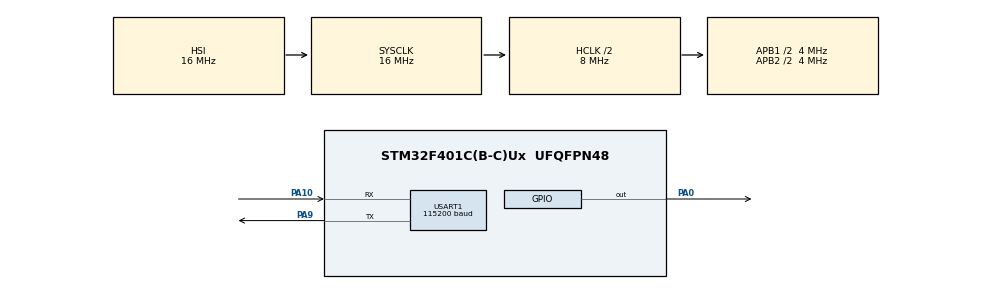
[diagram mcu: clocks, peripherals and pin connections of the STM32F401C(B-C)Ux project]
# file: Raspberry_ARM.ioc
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Mcu.Family=STM32F4
Mcu.Name=STM32F401C(B-C)Ux
Mcu.Package=UFQFPN48
NVIC.PriorityGroup=NVIC_PRIORITYGROUP_4
NVIC.USART1_IRQn=true\:0\:0\:false\:false\:true\:true\:true\:true
PA0-WKUP.Signal=GPIO_Output
PA10.Mode=Asynchronous
PA10.Signal=USART1_RX
PA9.Mode=Asynchronous
PA9.Signal=USART1_TX
ProjectManager.HeapSize=0x200
ProjectManager.StackSize=0x400
ProjectManager.TargetToolchain=STM32CubeIDE
RCC.AHBCLKDivider=RCC_SYSCLK_DIV2
RCC.AHBFreq_Value=8000000
RCC.APB1CLKDivider=RCC_HCLK_DIV2
RCC.APB1Freq_Value=4000000
RCC.APB1TimFreq_Value=8000000
RCC.APB2CLKDivider=RCC_HCLK_DIV2
RCC.APB2Freq_Value=4000000
RCC.APB2TimFreq_Value=8000000
RCC.CortexFreq_Value=8000000
RCC.HCLKFreq_Value=8000000
RCC.HSE_VALUE=25000000
RCC.HSI_VALUE=16000000
RCC.LSE_VALUE=32768
RCC.SYSCLKFreq_VALUE=16000000
RCC.VCOOutputFreq_Value=192000000
USART1.BaudRate=115200
USART1.VirtualMode=VM_ASYNC
board=custom

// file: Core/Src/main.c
/* USER CODE BEGIN Header */
/**
 ******************************************************************************
 * @file           : main.c
 * @brief          : Main program body
 ******************************************************************************
 * @attention
 *
 * Copyright (c) 2023 STMicroelectronics.
 * All rights reserved.
 *
 * This software is licensed under terms that can be found in the LICENSE file
 * in the root directory of this software component.
 * If no LICENSE file comes with this software, it is provided AS-IS.
 *
 ******************************************************************************
 */
/* USER CODE END Header */
#include "main.h"

/* USER CODE BEGIN PD */
#define SIZE_OF_BUFFER    1
#define LED_PORT          GPIOA
#define LED_PIN           GPIO_PIN_0
/* USER CODE END PD */

UART_HandleTypeDef huart1;

void SystemClock_Config(void);
static void MX_GPIO_Init(void);
static void MX_USART1_UART_Init(void);
/* USER CODE BEGIN PFP */
void LED_ON(void);
void LED_OFF(void);
/* USER CODE END PFP */

int main(void)
{
  /* USER CODE BEGIN 1 */
	uint8_t RecieveBuffer = 22;
  /* USER CODE END 1 */

  /* MCU Configuration--------------------------------------------------------*/

  /* Reset of all peripherals, Initializes the Flash interface and the Systick. */
  HAL_Init();

  /* Configure the system clock */
  SystemClock_Config();

  /* Initialize all configured peripherals */
  MX_GPIO_Init();
  MX_USART1_UART_Init();
  /* USER CODE BEGIN 2 */
//	HAL_GPIO_WritePin(GPIOA, GPIO_PIN_0, GPIO_PIN_SET);

  /* USER CODE END 2 */

  /* Infinite loop */
	while (1)
	{

    /* USER CODE BEGIN 3 */
		HAL_UART_Receive(&huart1, &RecieveBuffer,SIZE_OF_BUFFER, 20);
		if(RecieveBuffer == 'O'){
			LED_ON();
		}
		else if (RecieveBuffer == 'F'){
			LED_OFF();
		}
		else{
			//Do Nothing
		}
	}
  /* USER CODE END 3 */
}

void SystemClock_Config(void)
{
  RCC_OscInitTypeDef RCC_OscInitStruct = {0};
  RCC_ClkInitTypeDef RCC_ClkInitStruct = {0};

  /** Configure the main internal regulator output voltage
  */
  __HAL_RCC_PWR_CLK_ENABLE();
  __HAL_PWR_VOLTAGESCALING_CONFIG(PWR_REGULATOR_VOLTAGE_SCALE2);

  /** Initializes the RCC Oscillators according to the specified parameters
  * in the RCC_OscInitTypeDef structure.
  */
  RCC_OscInitStruct.OscillatorType = RCC_OSCILLATORTYPE_HSI;
  RCC_OscInitStruct.HSIState = RCC_HSI_ON;
  RCC_OscInitStruct.HSICalibrationValue = RCC_HSICALIBRATION_DEFAULT;
  RCC_OscInitStruct.PLL.PLLState = RCC_PLL_NONE;
  if (HAL_RCC_OscConfig(&RCC_OscInitStruct) != HAL_OK)
  {
    Error_Handler();
  }

  /** Initializes the CPU, AHB and APB buses clocks
  */
  RCC_ClkInitStruct.ClockType = RCC_CLOCKTYPE_HCLK|RCC_CLOCKTYPE_SYSCLK
                              |RCC_CLOCKTYPE_PCLK1|RCC_CLOCKTYPE_PCLK2;
  RCC_ClkInitStruct.SYSCLKSource = RCC_SYSCLKSOURCE_HSI;
  RCC_ClkInitStruct.AHBCLKDivider = RCC_SYSCLK_DIV2;
  RCC_ClkInitStruct.APB1CLKDivider = RCC_HCLK_DIV2;
  RCC_ClkInitStruct.APB2CLKDivider = RCC_HCLK_DIV2;

  if (HAL_RCC_ClockConfig(&RCC_ClkInitStruct, FLASH_LATENCY_0) != HAL_OK)
  {
    Error_Handler();
  }
}

static void MX_USART1_UART_Init(void)
{

  huart1.Instance = USART1;
  huart1.Init.BaudRate = 9600;
  huart1.Init.WordLength = UART_WORDLENGTH_8B;
  huart1.Init.StopBits = UART_STOPBITS_1;
  huart1.Init.Parity = UART_PARITY_NONE;
  huart1.Init.Mode = UART_MODE_TX_RX;
  huart1.Init.HwFlowCtl = UART_HWCONTROL_NONE;
  huart1.Init.OverSampling = UART_OVERSAMPLING_16;
  if (HAL_UART_Init(&huart1) != HAL_OK)
  {
    Error_Handler();
  }

}

static void MX_GPIO_Init(void)
{
  GPIO_InitTypeDef GPIO_InitStruct = {0};

  /* GPIO Ports Clock Enable */
  __HAL_RCC_GPIOA_CLK_ENABLE();

  /*Configure GPIO pin Output Level */
  HAL_GPIO_WritePin(GPIOA, GPIO_PIN_0, GPIO_PIN_RESET);

  /*Configure GPIO pin : PA0 */
  GPIO_InitStruct.Pin = GPIO_PIN_0;
  GPIO_InitStruct.Mode = GPIO_MODE_OUTPUT_PP;
  GPIO_InitStruct.Pull = GPIO_NOPULL;
  GPIO_InitStruct.Speed = GPIO_SPEED_FREQ_LOW;
  HAL_GPIO_Init(GPIOA, &GPIO_InitStruct);

}

/* USER CODE BEGIN 4 */
void LED_OFF(void){
	HAL_GPIO_WritePin(LED_PORT, LED_PIN, GPIO_PIN_RESET);
}
void LED_ON(void){
	HAL_GPIO_WritePin(LED_PORT, LED_PIN, GPIO_PIN_SET);
}

/* USER CODE END 4 */

void Error_Handler(void)
{
	__disable_irq();
	while (1)
	{
	}
}
